# EFR32FG2DA020F256IM48 register map
Vendor: Silicon Labs; Series: EFR32; File version: A
Registers are 32-bit, read-write, reset 0x0 unless marked. A register's access mark holds for its fields unless they carry their own. Offsets are from the block's base; [hi:lo] are bit positions; {n}, {i} and the like mark numbered series.

## SMU_NS — SMU_NS Registers
Base 0x54008000
Same registers: SMU_S 0x44008000
0x00 IPVERSION ro reset 0x2
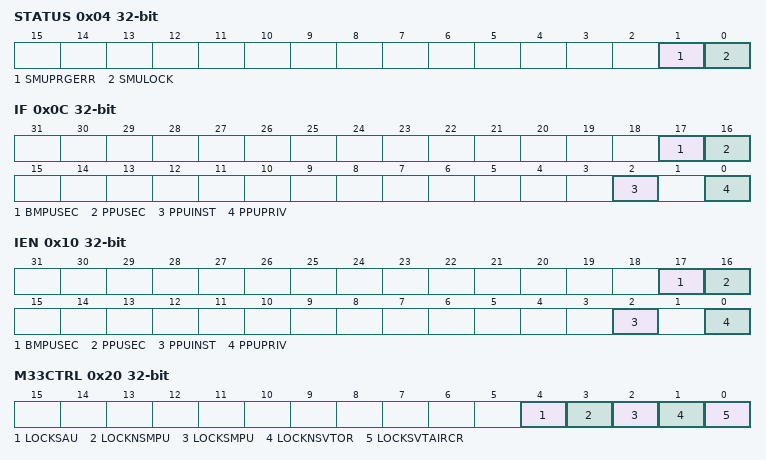
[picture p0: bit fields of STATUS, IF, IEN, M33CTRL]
0x04 STATUS ro
  [1] SMUPRGERR — SMU Programming Error
  [0] SMULOCK
    0=UNLOCKED (SMULOCK is Unlocked); 1=LOCKED (SMULOCK is Locked)
0x08 LOCK wo
  [23:0] SMULOCKKEY
    0xACCE55=UNLOCK (Unlocks Registers)
0x0C IF
  [17] BMPUSEC — BMPU Security Interrupt Flag
  [16] PPUSEC — PPU Security Interrupt Flag
  [2] PPUINST — PPU Instruction Interrupt Flag
  [0] PPUPRIV — PPU Privilege Interrupt Flag
0x10 IEN
  [17] BMPUSEC — BMPU Security Interrupt Enable
  [16] PPUSEC — PPU Security Interrupt Enable
  [2] PPUINST — PPU Instruction Interrupt Enable
  [0] PPUPRIV — PPU Privilege Interrupt Enable
0x20 M33CTRL — Holds the M33 control settings
  [4] LOCKSAU — LOCKSAU control of M33 CPU
  [3] LOCKNSMPU — LOCKNSMPU control of M33 CPU
  [2] LOCKSMPU — LOCKSMPU control of M33 CPU
  [1] LOCKNSVTOR — LOCKNSVTOR control of M33 CPU
  [0] LOCKSVTAIRCR — LOCKSVTAIRCR control of M33 CPU
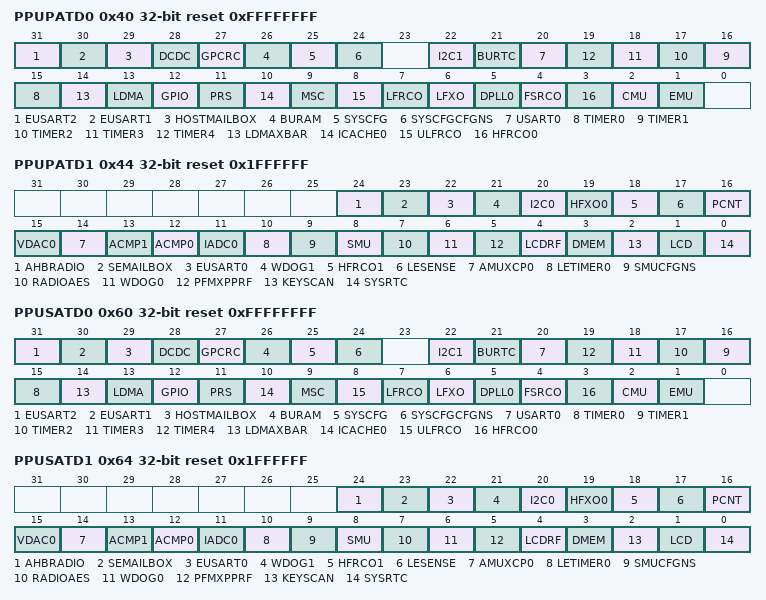
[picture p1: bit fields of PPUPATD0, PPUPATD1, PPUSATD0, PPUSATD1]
0x40 PPUPATD0 reset 0xFFFFFFFF — Set peripheral bits to 1 to mark as privileged access only
  [31] EUSART2 — EUSART2 Privileged Access
  [30] EUSART1 — EUSART1 Privileged Access
  [29] HOSTMAILBOX — HOSTMAILBOX Privileged Access
  [28] DCDC — DCDC Privileged Access
  [27] GPCRC — GPCRC Privileged Access
  [26] BURAM — BURAM Privileged Access
  [25] SYSCFG — SYSCFG Privileged Access
  [24] SYSCFGCFGNS — SYSCFGCFGNS Privileged Access
  [22] I2C1 — I2C1 Privileged Access
  [21] BURTC — BURTC Privileged Access
  [20] USART0 — USART0 Privileged Access
  [n+15] TIMER{n} (n=0..4) — TIMER{n} Privileged Access
  [14] LDMAXBAR — LDMAXBAR Privileged Access
  [13] LDMA — LDMA Privileged Access
  [12] GPIO — GPIO Privileged Access
  [11] PRS — PRS Privileged Access
  [10] ICACHE0 — ICACHE0 Privileged Access
  [9] MSC — MSC Privileged Access
  [8] ULFRCO — ULFRCO Privileged Access
  [7] LFRCO — LFRCO Privileged Access
  [6] LFXO — LFXO Privileged Access
  [5] DPLL0 — DPLL0 Privileged Access
  [4] FSRCO — FSRCO Privileged Access
  [3] HFRCO0 — HFRCO0 Privileged Access
  [2] CMU — CMU Privileged Access
  [1] EMU — EMU Privileged Access
0x44 PPUPATD1 reset 0x1FFFFFF — Set peripheral bits to 1 to mark as privileged access only
  [24] AHBRADIO — AHBRADIO Privileged Access
  [23] SEMAILBOX — SEMAILBOX Privileged Access
  [22] EUSART0 — EUSART0 Privileged Access
  [21] WDOG1 — WDOG1 Privileged Access
  [20] I2C0 — I2C0 Privileged Access
  [19] HFXO0 — HFXO0 Privileged Access
  [18] HFRCO1 — HFRCO1 Privileged Access
  [17] LESENSE — LESENSE Privileged Access
  [16] PCNT — PCNT Privileged Access
  [15] VDAC0 — VDAC0 Privileged Access
  [14] AMUXCP0 — AMUXCP0 Privileged Access
  [13] ACMP1 — ACMP1 Privileged Access
  [12] ACMP0 — ACMP0 Privileged Access
  [11] IADC0 — IADC0 Privileged Access
  [10] LETIMER0 — LETIMER0 Privileged Access
  [9] SMUCFGNS — SMUCFGNS Privileged Access
  [8] SMU — SMU Privileged Access
  [7] RADIOAES — RADIOAES Privileged Access
  [6] WDOG0 — WDOG0 Privileged Access
  [5] PFMXPPRF — PFMXPPRF Privileged Access
  [4] LCDRF — LCDRF Privileged Access
  [3] DMEM — DMEM Privileged Access
  [2] KEYSCAN — KEYSCAN Privileged Access
  [1] LCD — LCD Privileged Access
  [0] SYSRTC — SYSRTC Privileged Access
0x60 PPUSATD0 reset 0xFFFFFFFF — Set peripheral bits to 1 to mark as secure access only
  [31] EUSART2 — EUSART2 Secure Access
  [30] EUSART1 — EUSART1 Secure Access
  [29] HOSTMAILBOX — HOSTMAILBOX Secure Access
  [28] DCDC — DCDC Secure Access
  [27] GPCRC — GPCRC Secure Access
  [26] BURAM — BURAM Secure Access
  [25] SYSCFG — SYSCFG Secure Access
  [24] SYSCFGCFGNS — SYSCFGCFGNS Secure Access
  [22] I2C1 — I2C1 Secure Access
  [21] BURTC — BURTC Secure Access
  [20] USART0 — USART0 Secure Access
  [n+15] TIMER{n} (n=0..4) — TIMER{n} Secure Access
  [14] LDMAXBAR — LDMAXBAR Secure Access
  [13] LDMA — LDMA Secure Access
  [12] GPIO — GPIO Secure Access
  [11] PRS — PRS Secure Access
  [10] ICACHE0 — ICACHE0 Secure Access
  [9] MSC — MSC Secure Access
  [8] ULFRCO — ULFRCO Secure Access
  [7] LFRCO — LFRCO Secure Access
  [6] LFXO — LFXO Secure Access
  [5] DPLL0 — DPLL0 Secure Access
  [4] FSRCO — FSRCO Secure Access
  [3] HFRCO0 — HFRCO0 Secure Access
  [2] CMU — CMU Secure Access
  [1] EMU — EMU Secure Access
0x64 PPUSATD1 reset 0x1FFFFFF — Set peripheral bits to 1 to mark as secure access only
  [24] AHBRADIO — AHBRADIO Secure Access
  [23] SEMAILBOX — SEMAILBOX Secure Access
  [22] EUSART0 — EUSART0 Secure Access
  [21] WDOG1 — WDOG1 Secure Access
  [20] I2C0 — I2C0 Secure Access
  [19] HFXO0 — HFXO0 Secure Access
  [18] HFRCO1 — HFRCO1 Secure Access
  [17] LESENSE — LESENSE Secure Access
  [16] PCNT — PCNT Secure Access
  [15] VDAC0 — VDAC0 Secure Access
  [14] AMUXCP0 — AMUXCP0 Secure Access
  [13] ACMP1 — ACMP1 Secure Access
  [12] ACMP0 — ACMP0 Secure Access
  [11] IADC0 — IADC0 Secure Access
  [10] LETIMER0 — LETIMER0 Secure Access
  [9] SMUCFGNS — SMUCFGNS Secure Access
  [8] SMU — SMU Secure Access
  [7] RADIOAES — RADIOAES Secure Access
  [6] WDOG0 — WDOG0 Secure Access
  [5] PFMXPPRF — PFMXPPRF Secure Access
  [4] LCDRF — LCDRF Secure Access
  [3] DMEM — DMEM Secure Access
  [2] KEYSCAN — KEYSCAN Secure Access
  [1] LCD — LCD Secure Access
  [0] SYSRTC — SYSRTC Secure Access
0x140 PPUFS ro
  [7:0] PPUFSPERIPHID — Peripheral ID
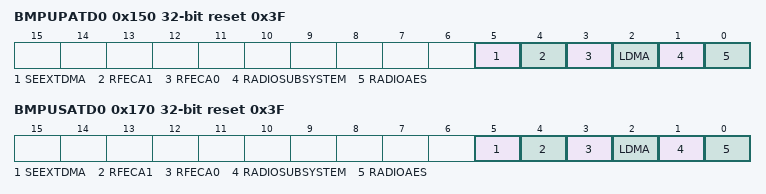
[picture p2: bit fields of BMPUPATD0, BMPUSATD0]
0x150 BMPUPATD0 reset 0x3F — Set master bits to 1 to mark as a privileged master
  [5] SEEXTDMA — SEEXTDMA Privileged Mode
  [4] RFECA1 — RFECA1 Privileged Mode
  [3] RFECA0 — RFECA0 Privileged Mode
  [2] LDMA — LDMA Privileged Mode
  [1] RADIOSUBSYSTEM — RADIOSUBSYSTEM Privileged Mode
  [0] RADIOAES — RADIOAES Privileged Mode
0x170 BMPUSATD0 reset 0x3F — Set master bits to 1 to mark as a secure master
  [5] SEEXTDMA — SEEXTDMA Secure Mode
  [4] RFECA1 — RFECA1 Secure Mode
  [3] RFECA0 — RFECA0 Secure Mode
  [2] LDMA — LDMA Secure Mode
  [1] RADIOSUBSYSTEM — RADIOSUBSYSTEM Secure Mode
  [0] RADIOAES — RADIOAES Secure Mode
0x250 BMPUFS ro
  [7:0] BMPUFSMASTERID — Bus Manager ID
0x254 BMPUFSADDR ro
  [31:0] BMPUFSADDR — Fault Address
0x260 ESAURTYPES0
  [12] ESAUR3NS — Region 3 Non-Secure
0x264 ESAURTYPES1
  [12] ESAUR11NS — Region 11 Non-Secure
0x270 ESAUMRB01 reset 0xA000000
  [27:12] ESAUMRB01 — Moveable Region Boundary 0-1
0x274 ESAUMRB12 reset 0xC000000
  [27:12] ESAUMRB12 — Moveable Region Boundary 1-2
0x280 ESAUMRB45 reset 0x2000000
  [27:12] ESAUMRB45 — Moveable Region Boundary 4-5
0x284 ESAUMRB56 reset 0x4000000
  [27:12] ESAUMRB56 — Moveable Region Boundary 5-6
